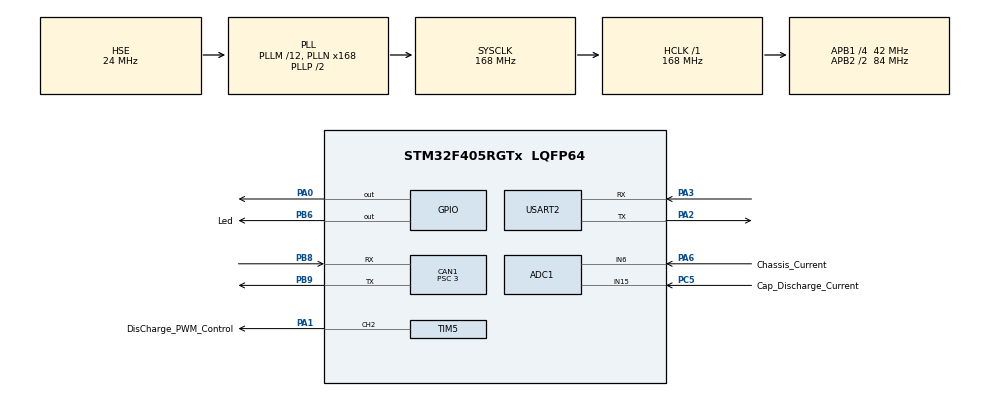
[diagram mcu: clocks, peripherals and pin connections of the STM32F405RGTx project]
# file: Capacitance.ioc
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ADC1.Channel-0\#ChannelRegularConversion=ADC_CHANNEL_6
ADC1.Channel-1\#ChannelRegularConversion=ADC_CHANNEL_15
ADC1.ContinuousConvMode=DISABLE
ADC1.DMAContinuousRequests=ENABLE
ADC1.ExternalTrigConv=ADC_EXTERNALTRIGCONV_T3_TRGO
ADC1.NbrOfConversion=2
ADC1.NbrOfConversionFlag=1
ADC1.Rank-0\#ChannelRegularConversion=1
ADC1.Rank-1\#ChannelRegularConversion=2
ADC1.SamplingTime-0\#ChannelRegularConversion=ADC_SAMPLETIME_15CYCLES
ADC1.SamplingTime-1\#ChannelRegularConversion=ADC_SAMPLETIME_15CYCLES
ADC1.ScanConvMode=ENABLE
ADC1.master=1
CAN1.ABOM=ENABLE
CAN1.BS1=CAN_BS1_11TQ
CAN1.BS2=CAN_BS2_2TQ
CAN1.CalculateTimeQuantum=71.42857142857143
CAN1.Prescaler=3
Dma.ADC1.0.Direction=DMA_PERIPH_TO_MEMORY
Dma.ADC1.0.FIFOMode=DMA_FIFOMODE_DISABLE
Dma.ADC1.0.Instance=DMA2_Stream0
Dma.ADC1.0.MemDataAlignment=DMA_MDATAALIGN_HALFWORD
Dma.ADC1.0.MemInc=DMA_MINC_ENABLE
Dma.ADC1.0.Mode=DMA_CIRCULAR
Dma.ADC1.0.PeriphDataAlignment=DMA_PDATAALIGN_HALFWORD
Dma.ADC1.0.PeriphInc=DMA_PINC_DISABLE
Dma.ADC1.0.Priority=DMA_PRIORITY_VERY_HIGH
Dma.Request0=ADC1
Mcu.Family=STM32F4
Mcu.Name=STM32F405RGTx
Mcu.Package=LQFP64
NVIC.ADC_IRQn=true\:0\:0\:false\:false\:true\:true\:true
NVIC.CAN1_RX0_IRQn=true\:0\:0\:false\:false\:true\:true\:true
NVIC.CAN1_TX_IRQn=true\:0\:0\:false\:false\:true\:true\:true
NVIC.DMA2_Stream0_IRQn=true\:0\:0\:false\:false\:true\:false\:true
NVIC.PriorityGroup=NVIC_PRIORITYGROUP_4
NVIC.TIM3_IRQn=true\:0\:0\:false\:false\:true\:true\:true
NVIC.TIM5_IRQn=true\:0\:0\:false\:false\:true\:true\:true
NVIC.TIM6_DAC_IRQn=true\:0\:0\:false\:false\:true\:true\:true
NVIC.USART2_IRQn=true\:0\:0\:false\:false\:true\:true\:true
PA0-WKUP.Signal=GPIO_Output
PA1.GPIO_Label=DisCharge_PWM_Control
PA1.GPIO_Speed=GPIO_SPEED_FREQ_VERY_HIGH
PA1.Signal=S_TIM5_CH2
PA13.Mode=Serial_Wire
PA13.Signal=SYS_JTMS-SWDIO
PA14.Mode=Serial_Wire
PA14.Signal=SYS_JTCK-SWCLK
PA2.Mode=Asynchronous
PA2.Signal=USART2_TX
PA3.Mode=Asynchronous
PA3.Signal=USART2_RX
PA6.GPIO_Label=Chassis_Current
PA6.Signal=ADCx_IN6
PB6.GPIO_Label=Led
PB6.Signal=GPIO_Output
PB8.Mode=Master
PB8.Signal=CAN1_RX
PB9.Mode=Master
PB9.Signal=CAN1_TX
PC5.GPIO_Label=Cap_Discharge_Current
PC5.Signal=ADCx_IN15
PH0-OSC_IN.Mode=HSE-External-Oscillator
PH0-OSC_IN.Signal=RCC_OSC_IN
PH1-OSC_OUT.Mode=HSE-External-Oscillator
PH1-OSC_OUT.Signal=RCC_OSC_OUT
ProjectManager.HeapSize=0x200
ProjectManager.StackSize=0x400
ProjectManager.TargetToolchain=MDK-ARM V5
RCC.48MHZClocksFreq_Value=84000000
RCC.AHBFreq_Value=168000000
RCC.APB1CLKDivider=RCC_HCLK_DIV4
RCC.APB1Freq_Value=42000000
RCC.APB1TimFreq_Value=84000000
RCC.APB2CLKDivider=RCC_HCLK_DIV2
RCC.APB2Freq_Value=84000000
RCC.APB2TimFreq_Value=168000000
RCC.CortexFreq_Value=168000000
RCC.HCLKFreq_Value=168000000
RCC.HSE_VALUE=24000000
RCC.HSI_VALUE=16000000
RCC.LSE_VALUE=32768
RCC.PLLM=12
RCC.PLLN=168
RCC.PLLSourceVirtual=RCC_PLLSOURCE_HSE
RCC.SYSCLKFreq_VALUE=168000000
RCC.SYSCLKSource=RCC_SYSCLKSOURCE_PLLCLK
RCC.VCOOutputFreq_Value=336000000
SH.ADCx_IN15.0=ADC1_IN15,IN15
SH.ADCx_IN6.0=ADC1_IN6,IN6
SH.S_TIM5_CH2.0=TIM5_CH2,PWM Generation2 CH2
TIM3.AutoReloadPreload=TIM_AUTORELOAD_PRELOAD_DISABLE
TIM3.Period=279
TIM3.Prescaler=0
TIM3.TIM_MasterOutputTrigger=TIM_TRGO_UPDATE
TIM5.Channel-PWM\ Generation2\ CH2=TIM_CHANNEL_2
TIM5.Period=8399
TIM5.Prescaler=0
TIM6.Period=9999
TIM6.Prescaler=8399
TIM6.TIM_MasterOutputTrigger=TIM_TRGO_RESET
USART2.VirtualMode=VM_ASYNC
VP_TIM3_VS_ClockSourceINT.Mode=Internal
VP_TIM5_VS_ClockSourceINT.Mode=Internal
VP_TIM6_VS_ClockSourceINT.Mode=Enable_Timer
board=custom

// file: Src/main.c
/* USER CODE BEGIN Header */
/**
  ******************************************************************************
  * @file           : main.c
  * @brief          : Main program body
  ******************************************************************************
  * @attention
  *
  * <h2><center>&copy; Copyright (c) 2019 STMicroelectronics.
  * All rights reserved.</center></h2>
  *
  * This software component is licensed by ST under BSD 3-Clause license,
  * the "License"; You may not use this file except in compliance with the
  * License. You may obtain a copy of the License at:
  *                        opensource.org/licenses/BSD-3-Clause
  *
  ******************************************************************************
  */
/* USER CODE END Header */

#include "main.h"
#include "adc.h"
#include "can.h"
#include "dma.h"
#include "tim.h"
#include "usart.h"
#include "gpio.h"

/* USER CODE BEGIN Includes */
#include "bsp_can.h"
#include "bsp_uart.h"
#include "stdio.h"
#include "cap_Ctrl.h"
/* USER CODE END Includes */

/* USER CODE BEGIN PTD */
OFFLINE_COUNT_STRUCT FPS;

/* USER CODE END PTD */

void SystemClock_Config(void);

int main(void)
{

  /* MCU Configuration--------------------------------------------------------*/

  /* Reset of all peripherals, Initializes the Flash interface and the Systick. */
  HAL_Init();

  /* Configure the system clock */
  SystemClock_Config();

  /* Initialize all configured peripherals */
  MX_GPIO_Init();
  MX_DMA_Init();
  MX_USART2_UART_Init();
  MX_ADC1_Init();
  MX_TIM3_Init();
  MX_CAN1_Init();
  MX_TIM6_Init();
  MX_TIM5_Init();
  /* USER CODE BEGIN 2 */
	HAL_GPIO_WritePin(GPIOA, GPIO_PIN_0, GPIO_PIN_SET);

	MY_CAN1_ENABLE();
	MY_UART_INIT();

	/* cap info init */
	CapInfo_Init();

	/* start the timer */
	HAL_TIM_Base_Start_IT(&htim3);
	HAL_TIM_Base_Start_IT(&htim6);
	HAL_TIM_Base_Start_IT(&htim5);
  HAL_TIM_PWM_Start(&htim5, TIM_CHANNEL_2); // beep
	/* start the dma of adc1 */
	HAL_ADC_Start_DMA(&hadc1, (uint32_t*) cap_info.adc1_rx_buff, 2);

	/* config the relay */

  /* USER CODE END 2 */

  /* Infinite loop */
  while (1)
  {

    /* USER CODE BEGIN 3 */
		//printf("/************ System Running Well! *****************/\r\n");
  }
  /* USER CODE END 3 */
}

void SystemClock_Config(void)
{
  RCC_OscInitTypeDef RCC_OscInitStruct = {0};
  RCC_ClkInitTypeDef RCC_ClkInitStruct = {0};

  /** Configure the main internal regulator output voltage
  */
  __HAL_RCC_PWR_CLK_ENABLE();
  __HAL_PWR_VOLTAGESCALING_CONFIG(PWR_REGULATOR_VOLTAGE_SCALE1);
  /** Initializes the CPU, AHB and APB busses clocks
  */
  RCC_OscInitStruct.OscillatorType = RCC_OSCILLATORTYPE_HSE;
  RCC_OscInitStruct.HSEState = RCC_HSE_ON;
  RCC_OscInitStruct.PLL.PLLState = RCC_PLL_ON;
  RCC_OscInitStruct.PLL.PLLSource = RCC_PLLSOURCE_HSE;
  RCC_OscInitStruct.PLL.PLLM = 12;
  RCC_OscInitStruct.PLL.PLLN = 168;
  RCC_OscInitStruct.PLL.PLLP = RCC_PLLP_DIV2;
  RCC_OscInitStruct.PLL.PLLQ = 4;
  if (HAL_RCC_OscConfig(&RCC_OscInitStruct) != HAL_OK)
  {
    Error_Handler();
  }
  /** Initializes the CPU, AHB and APB busses clocks
  */
  RCC_ClkInitStruct.ClockType = RCC_CLOCKTYPE_HCLK|RCC_CLOCKTYPE_SYSCLK
                              |RCC_CLOCKTYPE_PCLK1|RCC_CLOCKTYPE_PCLK2;
  RCC_ClkInitStruct.SYSCLKSource = RCC_SYSCLKSOURCE_PLLCLK;
  RCC_ClkInitStruct.AHBCLKDivider = RCC_SYSCLK_DIV1;
  RCC_ClkInitStruct.APB1CLKDivider = RCC_HCLK_DIV4;
  RCC_ClkInitStruct.APB2CLKDivider = RCC_HCLK_DIV2;

  if (HAL_RCC_ClockConfig(&RCC_ClkInitStruct, FLASH_LATENCY_5) != HAL_OK)
  {
    Error_Handler();
  }
}

void Error_Handler(void)
{
}

/************************ (C) COPYRIGHT STMicroelectronics *****END OF FILE****/
